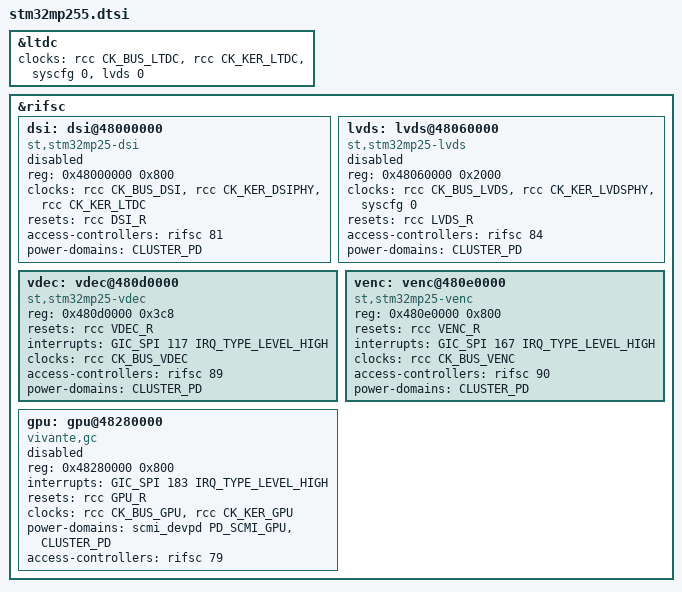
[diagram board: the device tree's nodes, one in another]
// SPDX-License-Identifier: (GPL-2.0-or-later OR BSD-3-Clause)
/*
 * Copyright (C) STMicroelectronics 2023 - All Rights Reserved
 * Author: Alexandre Torgue <alexandre.torgue@foss.st.com> for STMicroelectronics.
 */
#include <dt-bindings/power/st,stm32mp25-power.h>
#include "stm32mp253.dtsi"

&ltdc {
	clocks = <&rcc CK_BUS_LTDC>, <&rcc CK_KER_LTDC>, <&syscfg 0>, <&lvds 0>;
	clock-names = "bus", "ref", "lcd", "lvds";
};

&rifsc {
	dsi: dsi@48000000 {
		compatible = "st,stm32mp25-dsi";
		reg = <0x48000000 0x800>;
		#clock-cells = <0>;
		clocks = <&rcc CK_BUS_DSI>, <&rcc CK_KER_DSIPHY>,
			 <&rcc CK_KER_LTDC>;
		clock-names = "pclk", "ref", "px_clk";
		resets = <&rcc DSI_R>;
		reset-names = "apb";
		access-controllers = <&rifsc 81>;
		power-domains = <&CLUSTER_PD>;
		status = "disabled";
	};

	lvds: lvds@48060000 {
		#clock-cells = <0>;
		compatible = "st,stm32mp25-lvds";
		reg = <0x48060000 0x2000>;
		clocks = <&rcc CK_BUS_LVDS>, <&rcc CK_KER_LVDSPHY>, <&syscfg 0>;
		clock-names = "pclk", "ref", "pixclk";
		resets = <&rcc LVDS_R>;
		access-controllers = <&rifsc 84>;
		power-domains = <&CLUSTER_PD>;
		status = "disabled";
	};

	vdec: vdec@480d0000 {
		compatible = "st,stm32mp25-vdec";
		reg = <0x480d0000 0x3c8>;
		resets = <&rcc VDEC_R>;
		interrupts = <GIC_SPI 117 IRQ_TYPE_LEVEL_HIGH>;
		clocks = <&rcc CK_BUS_VDEC>;
		access-controllers = <&rifsc 89>;
		power-domains = <&CLUSTER_PD>;
	};

	venc: venc@480e0000 {
		compatible = "st,stm32mp25-venc";
		reg = <0x480e0000 0x800>;
		resets = <&rcc VENC_R>;
		interrupts = <GIC_SPI 167 IRQ_TYPE_LEVEL_HIGH>;
		clocks = <&rcc CK_BUS_VENC>;
		access-controllers = <&rifsc 90>;
		power-domains = <&CLUSTER_PD>;
	};

	gpu: gpu@48280000 {
		compatible = "vivante,gc";
		reg = <0x48280000 0x800>;
		interrupts = <GIC_SPI 183 IRQ_TYPE_LEVEL_HIGH>;
		resets = <&rcc GPU_R>;
		clock-names = "bus", "core";
		clocks = <&rcc CK_BUS_GPU>, <&rcc CK_KER_GPU>;
		power-domains = <&scmi_devpd PD_SCMI_GPU>, <&CLUSTER_PD>;
		access-controllers = <&rifsc 79>;
		status = "disabled";
	};
};
